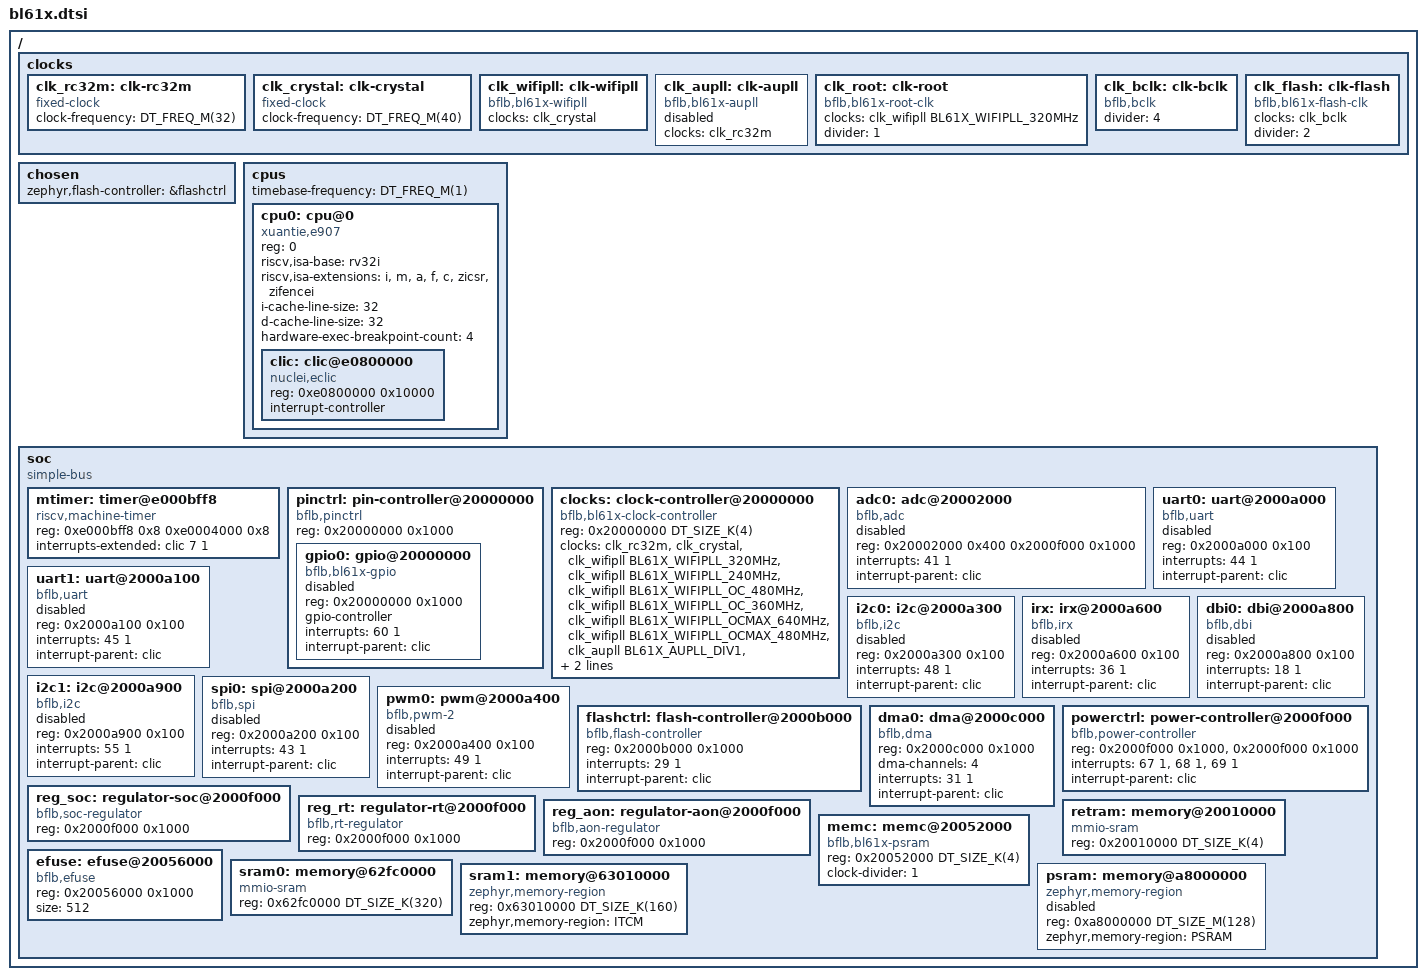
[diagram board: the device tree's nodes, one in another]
/*
 * Copyright (c) 2024-2026 MASSDRIVER EI (massdriver.space)
 *
 * SPDX-License-Identifier: Apache-2.0
 */

#include <freq.h>
#include <mem.h>
#include <zephyr/dt-bindings/pinctrl/bflb-common-pinctrl.h>
#include <zephyr/dt-bindings/pinctrl/bl61x-pinctrl.h>
#include <zephyr/dt-bindings/clock/bflb_bl61x_clock.h>
#include <zephyr/dt-bindings/gpio/gpio.h>
#include <zephyr/dt-bindings/input/input-event-codes.h>
#include <zephyr/dt-bindings/i2c/i2c.h>
#include <zephyr/dt-bindings/spi/spi.h>
#include <zephyr/dt-bindings/pwm/pwm.h>
#include <zephyr/dt-bindings/adc/adc.h>

/ {
	#address-cells = <1>;
	#size-cells = <1>;

	clocks {
		clk_rc32m: clk-rc32m {
			#clock-cells = <0>;
			compatible = "fixed-clock";
			clock-frequency = <DT_FREQ_M(32)>;
			status = "okay";
		};

		clk_crystal: clk-crystal {
			#clock-cells = <0>;
			compatible = "fixed-clock";
			clock-frequency = <DT_FREQ_M(40)>;
			status = "okay";
		};

		clk_wifipll: clk-wifipll {
			#clock-cells = <1>;
			compatible = "bflb,bl61x-wifipll";
			clocks = <&clk_crystal>;
			status = "okay";
		};

		clk_aupll: clk-aupll {
			#clock-cells = <1>;
			compatible = "bflb,bl61x-aupll";
			clocks = <&clk_rc32m>;
			status = "disabled";
		};

		clk_root: clk-root {
			#clock-cells = <0>;
			compatible = "bflb,bl61x-root-clk";
			clocks = <&clk_wifipll BL61X_WIFIPLL_320MHz>;
			divider = <1>;
			status = "okay";
		};

		clk_bclk: clk-bclk {
			#clock-cells = <0>;
			compatible = "bflb,bclk";
			divider = <4>;
			status = "okay";
		};

		clk_flash: clk-flash {
			#clock-cells = <0>;
			compatible = "bflb,bl61x-flash-clk";
			clocks = <&clk_bclk>;
			divider = <2>;
			status = "okay";
		};
	};

	chosen {
		zephyr,flash-controller = &flashctrl;
	};

	cpus {
		#address-cells = <1>;
		#size-cells = <0>;
		timebase-frequency = <DT_FREQ_M(1)>;

		cpu0: cpu@0 {
			device_type = "cpu";
			compatible = "xuantie,e907", "riscv";
			reg = <0>;
			riscv,isa-base = "rv32i";
			riscv,isa-extensions = "i", "m", "a", "f", "c", "zicsr", "zifencei";
			i-cache-line-size = <32>;
			d-cache-line-size = <32>;
			hardware-exec-breakpoint-count = <4>;
			status = "okay";

			#address-cells = <1>;
			#size-cells = <1>;

			clic: clic@e0800000 {
				compatible = "nuclei,eclic";
				reg = <0xe0800000 0x10000>;
				#address-cells = <0>;
				#interrupt-cells = <2>;
				interrupt-controller;
			};
		};
	};

	soc {
		compatible = "simple-bus";
		#address-cells = <1>;
		#size-cells = <1>;
		ranges;

		mtimer: timer@e000bff8 {
			compatible = "riscv,machine-timer";
			reg = <0xe000bff8 0x8 0xe0004000 0x8>;
			reg-names = "mtime", "mtimecmp";

			interrupts-extended = <&clic 7 1>;
		};

		pinctrl: pin-controller@20000000 {
			compatible = "bflb,pinctrl";
			reg = <0x20000000 0x1000>;
			ranges = <0x20000000 0x20000000 0x1000>;
			#address-cells = <1>;
			#size-cells = <1>;
			status = "okay";

			gpio0: gpio@20000000 {
				compatible = "bflb,bl61x-gpio";
				reg = <0x20000000 0x1000>;
				#gpio-cells = <2>;
				#bflb,pin-cells = <2>;
				status = "disabled";

				gpio-controller;
				interrupts = <60 1>;
				interrupt-parent = <&clic>;
			};
		};

		clocks: clock-controller@20000000 {
			compatible = "bflb,bl61x-clock-controller", "bflb,clock-controller";
			reg = <0x20000000 DT_SIZE_K(4)>;
			#clock-cells = <1>;
			status = "okay";
			clocks = <&clk_rc32m>, <&clk_crystal>,
				 <&clk_wifipll BL61X_WIFIPLL_320MHz>,
				 <&clk_wifipll BL61X_WIFIPLL_240MHz>,
				 <&clk_wifipll BL61X_WIFIPLL_OC_480MHz>,
				 <&clk_wifipll BL61X_WIFIPLL_OC_360MHz>,
				 <&clk_wifipll BL61X_WIFIPLL_OCMAX_640MHz>,
				 <&clk_wifipll BL61X_WIFIPLL_OCMAX_480MHz>,
				 <&clk_aupll BL61X_AUPLL_DIV1>, <&clk_aupll BL61X_AUPLL_DIV2>,
				 <&clk_root>, <&clk_bclk>, <&clk_flash>;
			clock-names = "rc32m", "crystal",
				      "wifipll_320",
				      "wifipll_240",
				      "wifipll_oc_480",
				      "wifipll_oc_360",
				      "wifipll_ocmax_640",
				      "wifipll_ocmax_480",
				      "aupll_div1", "aupll_div2",
				      "root", "bclk", "flash";
		};

		adc0: adc@20002000 {
			compatible = "bflb,adc";
			reg = <0x20002000 0x400 0x2000f000 0x1000>;
			#io-channel-cells = <1>;
			#address-cells = <1>;
			#size-cells = <0>;
			status = "disabled";

			interrupts = <41 1>;
			interrupt-parent = <&clic>;
		};

		uart0: uart@2000a000 {
			compatible = "bflb,uart";
			reg = <0x2000a000 0x100>;
			interrupts = <44 1>;
			interrupt-parent = <&clic>;
			status = "disabled";
		};

		uart1: uart@2000a100 {
			compatible = "bflb,uart";
			reg = <0x2000a100 0x100>;
			interrupts = <45 1>;
			interrupt-parent = <&clic>;
			status = "disabled";
		};

		i2c0: i2c@2000a300 {
			compatible = "bflb,i2c";
			reg = <0x2000a300 0x100>;
			#address-cells = <1>;
			#size-cells = <0>;
			status = "disabled";

			interrupts = <48 1>;
			interrupt-parent = <&clic>;
		};

		irx: irx@2000a600 {
			compatible = "bflb,irx";
			reg = <0x2000a600 0x100>;
			#address-cells = <1>;
			#size-cells = <0>;
			status = "disabled";

			interrupts = <36 1>;
			interrupt-parent = <&clic>;
		};

		dbi0: dbi@2000a800 {
			compatible = "bflb,dbi";
			reg = <0x2000a800 0x100>;
			#address-cells = <1>;
			#size-cells = <0>;
			status = "disabled";

			interrupts = <18 1>;
			interrupt-parent = <&clic>;
		};

		i2c1: i2c@2000a900 {
			compatible = "bflb,i2c";
			reg = <0x2000a900 0x100>;
			#address-cells = <1>;
			#size-cells = <0>;
			status = "disabled";

			interrupts = <55 1>;
			interrupt-parent = <&clic>;
		};

		spi0: spi@2000a200 {
			compatible = "bflb,spi";
			reg = <0x2000a200 0x100>;
			#address-cells = <1>;
			#size-cells = <0>;
			status = "disabled";

			interrupts = <43 1>;
			interrupt-parent = <&clic>;
		};

		pwm0: pwm@2000a400 {
			compatible = "bflb,pwm-2";
			reg = <0x2000a400 0x100>;
			#pwm-cells = <3>;
			status = "disabled";

			interrupts = <49 1>;
			interrupt-parent = <&clic>;
		};

		flashctrl: flash-controller@2000b000 {
			compatible = "bflb,flash-controller";
			reg = <0x2000b000 0x1000>;
			#address-cells = <1>;
			#size-cells = <1>;
			status = "okay";

			interrupts = <29 1>;
			interrupt-parent = <&clic>;
		};

		dma0: dma@2000c000 {
			compatible = "bflb,dma";
			reg = <0x2000c000 0x1000>;
			#dma-cells = <2>;
			dma-channels = <4>;

			interrupts = <31 1>;
			interrupt-parent = <&clic>;
		};

		powerctrl: power-controller@2000f000 {
			compatible = "bflb,power-controller";
			reg = <0x2000f000 0x1000>, <0x2000f000 0x1000>;
			reg-names = "hbn", "aon";
			status = "okay";

			interrupts = <67 1>, <68 1>, <69 1>;
			interrupt-parent = <&clic>;
			interrupt-names = "hbn0", "hbn1", "bor";
		};

		reg_soc: regulator-soc@2000f000 {
			compatible = "bflb,soc-regulator";
			reg = <0x2000f000 0x1000>;
			status = "okay";
		};

		reg_rt: regulator-rt@2000f000 {
			compatible = "bflb,rt-regulator";
			reg = <0x2000f000 0x1000>;
			status = "okay";
		};

		reg_aon: regulator-aon@2000f000 {
			compatible = "bflb,aon-regulator";
			reg = <0x2000f000 0x1000>;
			status = "okay";
		};

		retram: memory@20010000 {
			compatible = "mmio-sram";
			reg = <0x20010000 DT_SIZE_K(4)>;
		};

		memc: memc@20052000 {
			compatible = "bflb,bl61x-psram";
			reg = <0x20052000 DT_SIZE_K(4)>;
			clock-divider = <1>;
			status = "okay";
		};

		efuse: efuse@20056000 {
			compatible = "bflb,efuse";
			reg = <0x20056000 0x1000>;
			status = "okay";
			size = <512>;
		};

		sram0: memory@62fc0000 {
			compatible = "mmio-sram";
			reg = <0x62fc0000 DT_SIZE_K(320)>;
		};

		sram1: memory@63010000 {
			compatible = "zephyr,memory-region", "mmio-sram";
			reg = <0x63010000 DT_SIZE_K(160)>;
			zephyr,memory-region = "ITCM";
		};

		psram: memory@a8000000 {
			compatible = "zephyr,memory-region";
			reg = <0xa8000000 DT_SIZE_M(128)>;
			zephyr,memory-region = "PSRAM";
			status = "disabled";
		};
	};
};
